AUTOSAR XML (schema 4-2-2)
package /ASW_COM_STD_Package
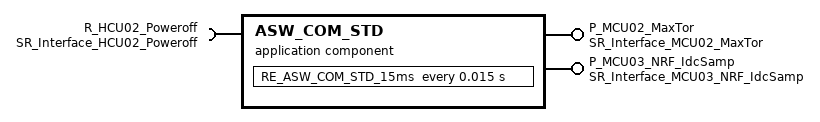
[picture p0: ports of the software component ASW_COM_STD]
  application sw component type ASW_COM_STD
    provide port P_MCU02_MaxTor: provided-interface=SR_Interface_MCU02_MaxTor
    provide port P_MCU03_NRF_IdcSamp: provided-interface=SR_Interface_MCU03_NRF_IdcSamp
    require port R_HCU02_Poweroff: nonqueued-receiver-com-spec{data-element=DE_HCU02_Poweroff, alive-timeout=0.3}, required-interface=SR_Interface_HCU02_Poweroff
    behavior IB_ASW_COM_STD
      timing event TE_ASW_COM_STD_15ms: start-on-event=RE_ASW_COM_STD_15ms, period=0.015
      runnable RE_ASW_COM_STD_15ms
        data-read-access-points:
          access READ_R_HCU02_Poweroff_DE_HCU02_Poweroff: accessed-variable=R_HCU02_Poweroff.DE_HCU02_Poweroff
        data-write-access-points:
          access WRITE_P_MCU02_MaxTor_DE_MCU02_MaxTor: accessed-variable=P_MCU02_MaxTor.DE_MCU02_MaxTor
          access WRITE_P_MCU03_NRF_IdcSamp_DE_MCU03_NRF_IdcSamp: accessed-variable=P_MCU03_NRF_IdcSamp.DE_MCU03_NRF_IdcSamp
